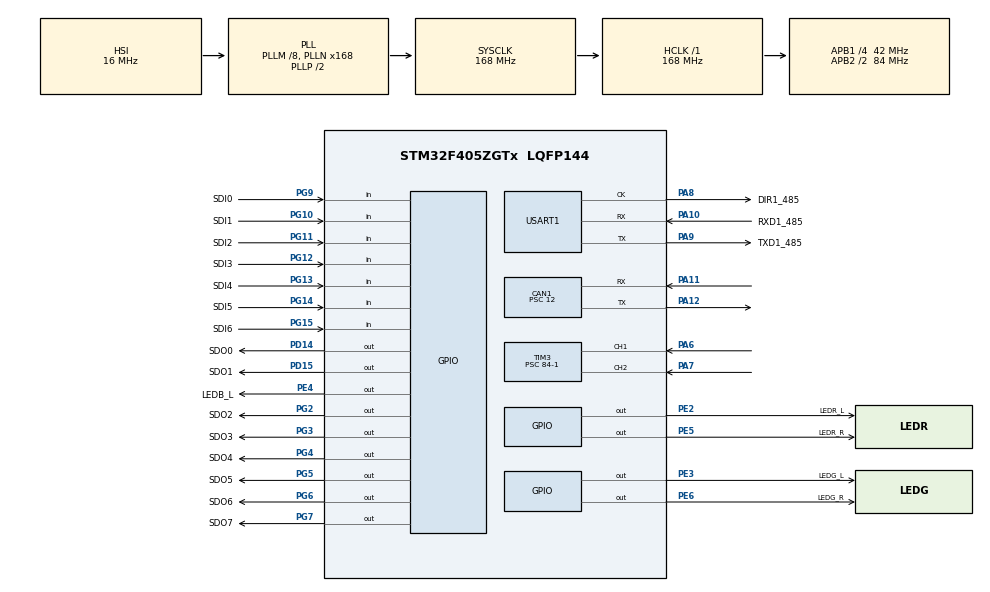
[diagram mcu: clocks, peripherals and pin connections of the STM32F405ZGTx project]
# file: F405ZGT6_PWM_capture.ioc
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CAN1.BS1=CAN_BS1_11TQ
CAN1.BS2=CAN_BS2_2TQ
CAN1.CalculateBaudRate=250000
CAN1.CalculateTimeBit=4000
CAN1.CalculateTimeQuantum=285.7142857142857
CAN1.Prescaler=12
Mcu.Family=STM32F4
Mcu.Name=STM32F405ZGTx
Mcu.Package=LQFP144
NVIC.CAN1_RX0_IRQn=true\:0\:0\:false\:false\:true\:true\:true\:true
NVIC.CAN1_RX1_IRQn=true\:0\:0\:false\:false\:true\:true\:true\:true
NVIC.CAN1_SCE_IRQn=true\:0\:0\:false\:false\:true\:true\:true\:true
NVIC.CAN1_TX_IRQn=true\:0\:0\:false\:false\:true\:true\:true\:true
NVIC.PriorityGroup=NVIC_PRIORITYGROUP_4
NVIC.TIM3_IRQn=true\:0\:0\:false\:false\:true\:true\:true\:true
PA10.GPIO_Label=RXD1_485
PA10.Mode=Synchronous
PA10.Signal=USART1_RX
PA11.Mode=CAN_Activate
PA11.Signal=CAN1_RX
PA12.Mode=CAN_Activate
PA12.Signal=CAN1_TX
PA13.Mode=JTAG_5_pins
PA13.Signal=SYS_JTMS-SWDIO
PA14.Mode=JTAG_5_pins
PA14.Signal=SYS_JTCK-SWCLK
PA15.Mode=JTAG_5_pins
PA15.Signal=SYS_JTDI
PA6.Signal=S_TIM3_CH1
PA7.Signal=S_TIM3_CH2
PA8.GPIO_Label=DIR1_485
PA8.Mode=Synchronous
PA8.Signal=USART1_CK
PA9.GPIO_Label=TXD1_485
PA9.Mode=Synchronous
PA9.Signal=USART1_TX
PB3.Mode=JTAG_5_pins
PB3.Signal=SYS_JTDO-SWO
PB4.Mode=JTAG_5_pins
PB4.Signal=SYS_JTRST
PD14.GPIO_Label=SDO0
PD14.Signal=GPIO_Output
PD15.GPIO_Label=SDO1
PD15.Signal=GPIO_Output
PE2.GPIO_Label=LEDR_L
PE2.Signal=GPIO_Output
PE3.GPIO_Label=LEDG_L
PE3.Signal=GPIO_Output
PE4.GPIO_Label=LEDB_L
PE4.Signal=GPIO_Output
PE5.GPIO_Label=LEDR_R
PE5.Signal=GPIO_Output
PE6.GPIO_Label=LEDG_R
PE6.Signal=GPIO_Output
PG10.GPIO_Label=SDI1
PG10.Signal=GPIO_Input
PG11.GPIO_Label=SDI2
PG11.Signal=GPIO_Input
PG12.GPIO_Label=SDI3
PG12.Signal=GPIO_Input
PG13.GPIO_Label=SDI4
PG13.Signal=GPIO_Input
PG14.GPIO_Label=SDI5
PG14.Signal=GPIO_Input
PG15.GPIO_Label=SDI6
PG15.Signal=GPIO_Input
PG2.GPIO_Label=SDO2
PG2.Signal=GPIO_Output
PG3.GPIO_Label=SDO3
PG3.Signal=GPIO_Output
PG4.GPIO_Label=SDO4
PG4.Signal=GPIO_Output
PG5.GPIO_Label=SDO5
PG5.Signal=GPIO_Output
PG6.GPIO_Label=SDO6
PG6.Signal=GPIO_Output
PG7.GPIO_Label=SDO7
PG7.Signal=GPIO_Output
PG9.GPIO_Label=SDI0
PG9.Signal=GPIO_Input
PH0-OSC_IN.Mode=HSE-External-Oscillator
PH0-OSC_IN.Signal=RCC_OSC_IN
PH1-OSC_OUT.Mode=HSE-External-Oscillator
PH1-OSC_OUT.Signal=RCC_OSC_OUT
ProjectManager.HeapSize=0x200
ProjectManager.StackSize=0x400
ProjectManager.TargetToolchain=STM32CubeIDE
RCC.48MHZClocksFreq_Value=84000000
RCC.AHBFreq_Value=168000000
RCC.APB1CLKDivider=RCC_HCLK_DIV4
RCC.APB1Freq_Value=42000000
RCC.APB1TimFreq_Value=84000000
RCC.APB2CLKDivider=RCC_HCLK_DIV2
RCC.APB2Freq_Value=84000000
RCC.APB2TimFreq_Value=168000000
RCC.CortexFreq_Value=168000000
RCC.HCLKFreq_Value=168000000
RCC.HSE_VALUE=8000000
RCC.HSI_VALUE=16000000
RCC.LSE_VALUE=32768
RCC.PLLM=8
RCC.PLLN=168
RCC.SYSCLKFreq_VALUE=168000000
RCC.SYSCLKSource=RCC_SYSCLKSOURCE_PLLCLK
RCC.VCOOutputFreq_Value=336000000
SH.S_TIM3_CH1.0=TIM3_CH1,Input_Capture1_from_TI1
SH.S_TIM3_CH2.0=TIM3_CH2,Input_Capture2_from_TI2
TIM3.Channel-Input_Capture1_from_TI1=TIM_CHANNEL_1
TIM3.Channel-Input_Capture2_from_TI2=TIM_CHANNEL_2
TIM3.ICPolarity_CH2=TIM_INPUTCHANNELPOLARITY_FALLING
TIM3.Period=10000-1
TIM3.Prescaler=84-1
USART1.VirtualMode=VM_SYNC
VP_TIM3_VS_ClockSourceINT.Mode=Internal
board=custom

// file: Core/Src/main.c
/* USER CODE BEGIN Header */
/**
  ******************************************************************************
  * @file           : main.c
  * @brief          : Main program body
  ******************************************************************************
  * @attention
  *
  * Copyright (c) 2024 STMicroelectronics.
  * All rights reserved.
  *
  * This software is licensed under terms that can be found in the LICENSE file
  * in the root directory of this software component.
  * If no LICENSE file comes with this software, it is provided AS-IS.
  *
  ******************************************************************************
  */
/* USER CODE END Header */
#include "main.h"

CAN_HandleTypeDef hcan1;

TIM_HandleTypeDef htim3;

USART_HandleTypeDef husart1;

void SystemClock_Config(void);
static void MX_GPIO_Init(void);
static void MX_CAN1_Init(void);
static void MX_USART1_Init(void);
static void MX_TIM3_Init(void);

int main(void)
{

  /* MCU Configuration--------------------------------------------------------*/

  /* Reset of all peripherals, Initializes the Flash interface and the Systick. */
  HAL_Init();

  /* Configure the system clock */
  SystemClock_Config();

  /* Initialize all configured peripherals */
  MX_GPIO_Init();
  MX_CAN1_Init();
  MX_USART1_Init();
  MX_TIM3_Init();
  /* USER CODE BEGIN 2 */
  HAL_TIM_IC_Start_IT(&htim3, TIM_CHANNEL_ALL);
  /* USER CODE END 2 */

  /* Infinite loop */
  while (1)
  {

  }
}

void SystemClock_Config(void)
{
  RCC_OscInitTypeDef RCC_OscInitStruct = {0};
  RCC_ClkInitTypeDef RCC_ClkInitStruct = {0};

  /** Configure the main internal regulator output voltage
  */
  __HAL_RCC_PWR_CLK_ENABLE();
  __HAL_PWR_VOLTAGESCALING_CONFIG(PWR_REGULATOR_VOLTAGE_SCALE1);

  /** Initializes the RCC Oscillators according to the specified parameters
  * in the RCC_OscInitTypeDef structure.
  */
  RCC_OscInitStruct.OscillatorType = RCC_OSCILLATORTYPE_HSI;
  RCC_OscInitStruct.HSIState = RCC_HSI_ON;
  RCC_OscInitStruct.HSICalibrationValue = RCC_HSICALIBRATION_DEFAULT;
  RCC_OscInitStruct.PLL.PLLState = RCC_PLL_ON;
  RCC_OscInitStruct.PLL.PLLSource = RCC_PLLSOURCE_HSI;
  RCC_OscInitStruct.PLL.PLLM = 8;
  RCC_OscInitStruct.PLL.PLLN = 168;
  RCC_OscInitStruct.PLL.PLLP = RCC_PLLP_DIV2;
  RCC_OscInitStruct.PLL.PLLQ = 4;
  if (HAL_RCC_OscConfig(&RCC_OscInitStruct) != HAL_OK)
  {
    Error_Handler();
  }

  /** Initializes the CPU, AHB and APB buses clocks
  */
  RCC_ClkInitStruct.ClockType = RCC_CLOCKTYPE_HCLK|RCC_CLOCKTYPE_SYSCLK
                              |RCC_CLOCKTYPE_PCLK1|RCC_CLOCKTYPE_PCLK2;
  RCC_ClkInitStruct.SYSCLKSource = RCC_SYSCLKSOURCE_PLLCLK;
  RCC_ClkInitStruct.AHBCLKDivider = RCC_SYSCLK_DIV1;
  RCC_ClkInitStruct.APB1CLKDivider = RCC_HCLK_DIV4;
  RCC_ClkInitStruct.APB2CLKDivider = RCC_HCLK_DIV2;

  if (HAL_RCC_ClockConfig(&RCC_ClkInitStruct, FLASH_LATENCY_5) != HAL_OK)
  {
    Error_Handler();
  }
}

static void MX_CAN1_Init(void)
{

  hcan1.Instance = CAN1;
  hcan1.Init.Prescaler = 12;
  hcan1.Init.Mode = CAN_MODE_NORMAL;
  hcan1.Init.SyncJumpWidth = CAN_SJW_1TQ;
  hcan1.Init.TimeSeg1 = CAN_BS1_11TQ;
  hcan1.Init.TimeSeg2 = CAN_BS2_2TQ;
  hcan1.Init.TimeTriggeredMode = DISABLE;
  hcan1.Init.AutoBusOff = DISABLE;
  hcan1.Init.AutoWakeUp = DISABLE;
  hcan1.Init.AutoRetransmission = DISABLE;
  hcan1.Init.ReceiveFifoLocked = DISABLE;
  hcan1.Init.TransmitFifoPriority = DISABLE;
  if (HAL_CAN_Init(&hcan1) != HAL_OK)
  {
    Error_Handler();
  }

}

static void MX_TIM3_Init(void)
{

  TIM_ClockConfigTypeDef sClockSourceConfig = {0};
  TIM_MasterConfigTypeDef sMasterConfig = {0};
  TIM_IC_InitTypeDef sConfigIC = {0};

  htim3.Instance = TIM3;
  htim3.Init.Prescaler = 84-1;
  htim3.Init.CounterMode = TIM_COUNTERMODE_UP;
  htim3.Init.Period = 10000-1;
  htim3.Init.ClockDivision = TIM_CLOCKDIVISION_DIV1;
  htim3.Init.AutoReloadPreload = TIM_AUTORELOAD_PRELOAD_DISABLE;
  if (HAL_TIM_Base_Init(&htim3) != HAL_OK)
  {
    Error_Handler();
  }
  sClockSourceConfig.ClockSource = TIM_CLOCKSOURCE_INTERNAL;
  if (HAL_TIM_ConfigClockSource(&htim3, &sClockSourceConfig) != HAL_OK)
  {
    Error_Handler();
  }
  if (HAL_TIM_IC_Init(&htim3) != HAL_OK)
  {
    Error_Handler();
  }
  sMasterConfig.MasterOutputTrigger = TIM_TRGO_RESET;
  sMasterConfig.MasterSlaveMode = TIM_MASTERSLAVEMODE_DISABLE;
  if (HAL_TIMEx_MasterConfigSynchronization(&htim3, &sMasterConfig) != HAL_OK)
  {
    Error_Handler();
  }
  sConfigIC.ICPolarity = TIM_INPUTCHANNELPOLARITY_RISING;
  sConfigIC.ICSelection = TIM_ICSELECTION_DIRECTTI;
  sConfigIC.ICPrescaler = TIM_ICPSC_DIV1;
  sConfigIC.ICFilter = 0;
  if (HAL_TIM_IC_ConfigChannel(&htim3, &sConfigIC, TIM_CHANNEL_1) != HAL_OK)
  {
    Error_Handler();
  }
  sConfigIC.ICPolarity = TIM_INPUTCHANNELPOLARITY_FALLING;
  if (HAL_TIM_IC_ConfigChannel(&htim3, &sConfigIC, TIM_CHANNEL_2) != HAL_OK)
  {
    Error_Handler();
  }

}

static void MX_USART1_Init(void)
{

  husart1.Instance = USART1;
  husart1.Init.BaudRate = 115200;
  husart1.Init.WordLength = USART_WORDLENGTH_8B;
  husart1.Init.StopBits = USART_STOPBITS_1;
  husart1.Init.Parity = USART_PARITY_NONE;
  husart1.Init.Mode = USART_MODE_TX_RX;
  husart1.Init.CLKPolarity = USART_POLARITY_LOW;
  husart1.Init.CLKPhase = USART_PHASE_1EDGE;
  husart1.Init.CLKLastBit = USART_LASTBIT_DISABLE;
  if (HAL_USART_Init(&husart1) != HAL_OK)
  {
    Error_Handler();
  }

}

static void MX_GPIO_Init(void)
{
  GPIO_InitTypeDef GPIO_InitStruct = {0};

  /* GPIO Ports Clock Enable */
  __HAL_RCC_GPIOE_CLK_ENABLE();
  __HAL_RCC_GPIOH_CLK_ENABLE();
  __HAL_RCC_GPIOA_CLK_ENABLE();
  __HAL_RCC_GPIOD_CLK_ENABLE();
  __HAL_RCC_GPIOG_CLK_ENABLE();
  __HAL_RCC_GPIOB_CLK_ENABLE();

  /*Configure GPIO pin Output Level */
  HAL_GPIO_WritePin(GPIOE, LEDR_L_Pin|LEDG_L_Pin|LEDB_L_Pin|LEDR_R_Pin
                          |LEDG_R_Pin, GPIO_PIN_RESET);

  /*Configure GPIO pin Output Level */
  HAL_GPIO_WritePin(GPIOD, SDO0_Pin|SDO1_Pin, GPIO_PIN_RESET);

  /*Configure GPIO pin Output Level */
  HAL_GPIO_WritePin(GPIOG, SDO2_Pin|SDO3_Pin|SDO4_Pin|SDO5_Pin
                          |SDO6_Pin|SDO7_Pin, GPIO_PIN_RESET);

  /*Configure GPIO pins : LEDR_L_Pin LEDG_L_Pin LEDB_L_Pin LEDR_R_Pin
                           LEDG_R_Pin */
  GPIO_InitStruct.Pin = LEDR_L_Pin|LEDG_L_Pin|LEDB_L_Pin|LEDR_R_Pin
                          |LEDG_R_Pin;
  GPIO_InitStruct.Mode = GPIO_MODE_OUTPUT_PP;
  GPIO_InitStruct.Pull = GPIO_NOPULL;
  GPIO_InitStruct.Speed = GPIO_SPEED_FREQ_LOW;
  HAL_GPIO_Init(GPIOE, &GPIO_InitStruct);

  /*Configure GPIO pins : SDO0_Pin SDO1_Pin */
  GPIO_InitStruct.Pin = SDO0_Pin|SDO1_Pin;
  GPIO_InitStruct.Mode = GPIO_MODE_OUTPUT_PP;
  GPIO_InitStruct.Pull = GPIO_NOPULL;
  GPIO_InitStruct.Speed = GPIO_SPEED_FREQ_LOW;
  HAL_GPIO_Init(GPIOD, &GPIO_InitStruct);

  /*Configure GPIO pins : SDO2_Pin SDO3_Pin SDO4_Pin SDO5_Pin
                           SDO6_Pin SDO7_Pin */
  GPIO_InitStruct.Pin = SDO2_Pin|SDO3_Pin|SDO4_Pin|SDO5_Pin
                          |SDO6_Pin|SDO7_Pin;
  GPIO_InitStruct.Mode = GPIO_MODE_OUTPUT_PP;
  GPIO_InitStruct.Pull = GPIO_NOPULL;
  GPIO_InitStruct.Speed = GPIO_SPEED_FREQ_LOW;
  HAL_GPIO_Init(GPIOG, &GPIO_InitStruct);

  /*Configure GPIO pins : SDI0_Pin SDI1_Pin SDI2_Pin SDI3_Pin
                           SDI4_Pin SDI5_Pin SDI6_Pin */
  GPIO_InitStruct.Pin = SDI0_Pin|SDI1_Pin|SDI2_Pin|SDI3_Pin
                          |SDI4_Pin|SDI5_Pin|SDI6_Pin;
  GPIO_InitStruct.Mode = GPIO_MODE_INPUT;
  GPIO_InitStruct.Pull = GPIO_NOPULL;
  HAL_GPIO_Init(GPIOG, &GPIO_InitStruct);

}

/* USER CODE BEGIN 4 */
void HAL_TIM_IC_CaptureCallback(TIM_HandleTypeDef *htim)
{
	if (htim->Instance == TIM2) {
		int a;
	}
}

/* USER CODE END 4 */

void Error_Handler(void)
{
  __disable_irq();
  while (1)
  {
  }
}
